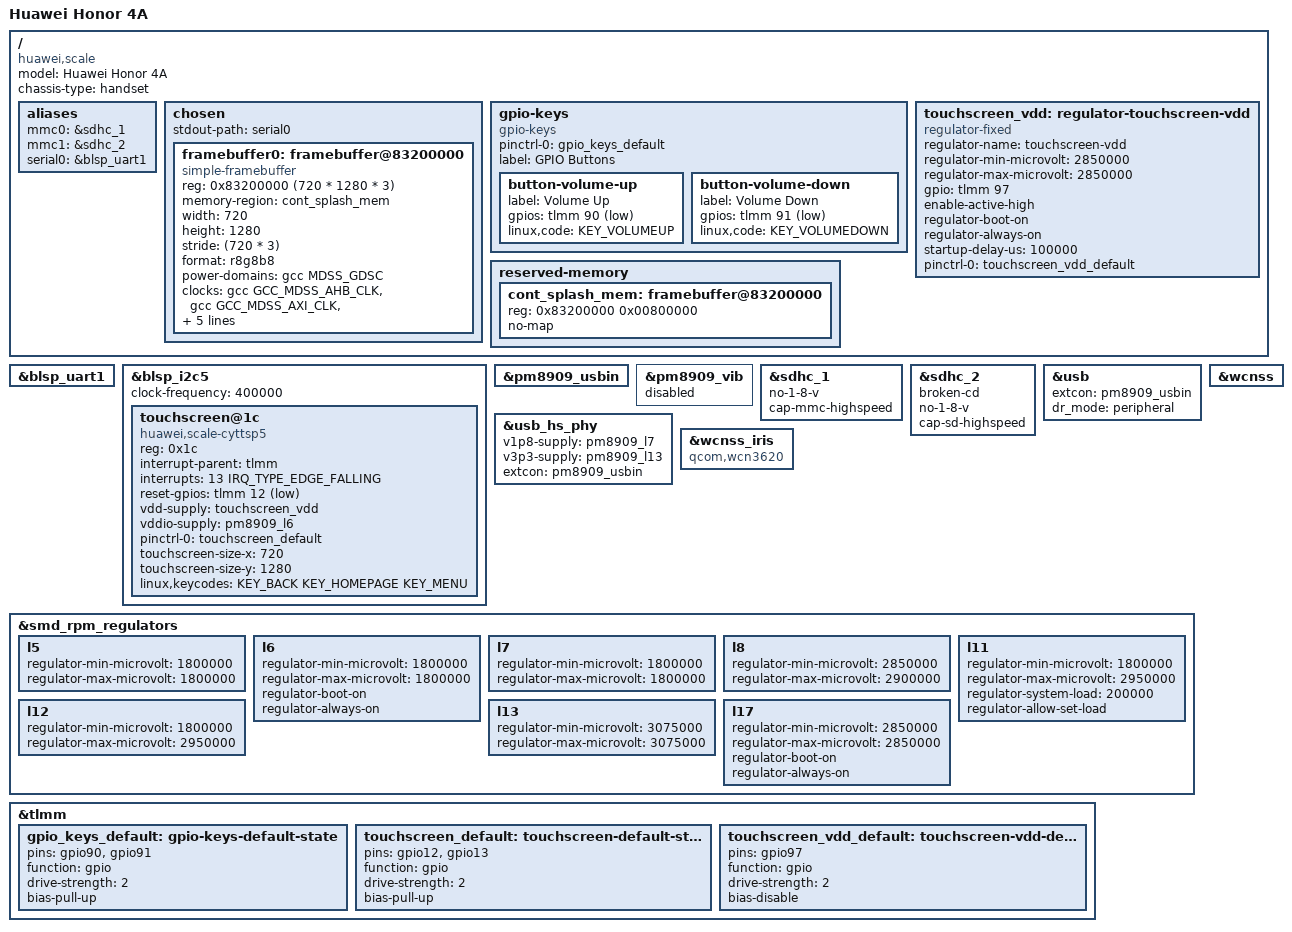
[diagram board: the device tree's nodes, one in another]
// SPDX-License-Identifier: GPL-2.0-only

/dts-v1/;

#include "qcom-msm8909-pm8909.dtsi"

#include <dt-bindings/gpio/gpio.h>
#include <dt-bindings/input/input.h>
#include <dt-bindings/interrupt-controller/irq.h>
#include <dt-bindings/leds/common.h>

/ {
	model = "Huawei Honor 4A";
	compatible = "huawei,scale", "qcom,msm8909";
	chassis-type = "handset";

	aliases {
		mmc0 = &sdhc_1;
		mmc1 = &sdhc_2;
		serial0 = &blsp_uart1;
	};

	chosen {
		#address-cells = <1>;
		#size-cells = <1>;
		ranges;

		stdout-path = "serial0";

		framebuffer0: framebuffer@83200000 {
			compatible = "simple-framebuffer";
			reg = <0x83200000 (720 * 1280 * 3)>;
			memory-region = <&cont_splash_mem>;

			width = <720>;
			height = <1280>;
			stride = <(720 * 3)>;
			format = "r8g8b8";

			power-domains = <&gcc MDSS_GDSC>;

			clocks = <&gcc GCC_MDSS_AHB_CLK>,
				 <&gcc GCC_MDSS_AXI_CLK>,
				 <&gcc GCC_MDSS_VSYNC_CLK>,
				 <&gcc GCC_MDSS_MDP_CLK>,
				 <&gcc GCC_MDSS_BYTE0_CLK>,
				 <&gcc GCC_MDSS_PCLK0_CLK>,
				 <&gcc GCC_MDSS_ESC0_CLK>;
		};
	};

	gpio-keys {
		compatible = "gpio-keys";

		pinctrl-0 = <&gpio_keys_default>;
		pinctrl-names = "default";

		label = "GPIO Buttons";

		button-volume-up {
			label = "Volume Up";
			gpios = <&tlmm 90 GPIO_ACTIVE_LOW>;
			linux,code = <KEY_VOLUMEUP>;
		};

		button-volume-down {
			label = "Volume Down";
			gpios = <&tlmm 91 GPIO_ACTIVE_LOW>;
			linux,code = <KEY_VOLUMEDOWN>;
		};
	};

	touchscreen_vdd: regulator-touchscreen-vdd {
		compatible = "regulator-fixed";
		regulator-name = "touchscreen-vdd";
		regulator-min-microvolt = <2850000>;
		regulator-max-microvolt = <2850000>;
		gpio = <&tlmm 97 GPIO_ACTIVE_HIGH>;
		enable-active-high;
		regulator-boot-on;
		regulator-always-on;
		startup-delay-us = <100000>;
		pinctrl-0 = <&touchscreen_vdd_default>;
		pinctrl-names = "default";
	};

	reserved-memory {
		#address-cells = <1>;
		#size-cells = <1>;
		ranges;

		cont_splash_mem: framebuffer@83200000 {
			reg = <0x83200000 0x00800000>;
			no-map;
		};
	};
};

&blsp_uart1 {
	status = "okay";
};

&blsp_i2c5 {
	clock-frequency = <400000>;
	status = "okay";

	touchscreen@1c {
		compatible = "huawei,scale-cyttsp5", "cypress,tt21000";
		reg = <0x1c>;

		interrupt-parent = <&tlmm>;
		interrupts = <13 IRQ_TYPE_EDGE_FALLING>;

		reset-gpios = <&tlmm 12 GPIO_ACTIVE_LOW>;
		vdd-supply = <&touchscreen_vdd>;
		vddio-supply = <&pm8909_l6>;

		pinctrl-0 = <&touchscreen_default>;
		pinctrl-names = "default";

		touchscreen-size-x = <720>;
		touchscreen-size-y = <1280>;
		linux,keycodes = <KEY_BACK KEY_HOMEPAGE KEY_MENU>;
		status = "okay";
	};
};

&pm8909_usbin {
	status = "okay";
};

&pm8909_vib {
	status = "disabled";
};

&sdhc_1 {
	/delete-property/ mmc-hs200-1_8v;
	/delete-property/ mmc-ddr-1_8v;
	no-1-8-v;
	cap-mmc-highspeed;
	status = "okay";
};

&sdhc_2 {
	broken-cd;
	no-1-8-v;
	cap-sd-highspeed;
	status = "okay";
};

&usb {
	extcon = <&pm8909_usbin>;
	dr_mode = "peripheral";
	status = "okay";
};

&usb_hs_phy {
	v1p8-supply = <&pm8909_l7>;
	v3p3-supply = <&pm8909_l13>;
	extcon = <&pm8909_usbin>;
};

&wcnss {
	status = "okay";
};

&wcnss_iris {
	compatible = "qcom,wcn3620";
	status = "okay";
};

&smd_rpm_regulators {
	l5 {
		regulator-min-microvolt = <1800000>;
		regulator-max-microvolt = <1800000>;
	};

	l6 {
		regulator-min-microvolt = <1800000>;
		regulator-max-microvolt = <1800000>;
		regulator-boot-on;
		regulator-always-on;
	};

	l7 {
		regulator-min-microvolt = <1800000>;
		regulator-max-microvolt = <1800000>;
	};

	l8 {
		regulator-min-microvolt = <2850000>;
		regulator-max-microvolt = <2900000>;
	};

	l11 {
		regulator-min-microvolt = <1800000>;
		regulator-max-microvolt = <2950000>;
		regulator-system-load = <200000>;
		regulator-allow-set-load;
	};

	l12 {
		regulator-min-microvolt = <1800000>;
		regulator-max-microvolt = <2950000>;
	};

	l13 {
		regulator-min-microvolt = <3075000>;
		regulator-max-microvolt = <3075000>;
	};

	l17 {
		regulator-min-microvolt = <2850000>;
		regulator-max-microvolt = <2850000>;
		regulator-boot-on;
		regulator-always-on;
	};
};

&tlmm {
	gpio_keys_default: gpio-keys-default-state {
		pins = "gpio90", "gpio91";
		function = "gpio";
		drive-strength = <2>;
		bias-pull-up;
	};

	touchscreen_default: touchscreen-default-state {
		pins = "gpio12", "gpio13";
		function = "gpio";
		drive-strength = <2>;
		bias-pull-up;
	};

	touchscreen_vdd_default: touchscreen-vdd-default-state {
		pins = "gpio97";
		function = "gpio";
		drive-strength = <2>;
		bias-disable;
	};
};
